# ESP32-P4 register map
Vendor: ESPRESSIF SYSTEMS (SHANGHAI) CO., LTD.; Series: ESP32 P-Series; File version: 3
CPU: RV32IMAFC r0p0, little endian, no MPU, FPU, 0 interrupt priority bits
Address unit: 32 bits
Registers are 32-bit, read-write, reset 0x0 unless marked. A register's access mark holds for its fields unless they carry their own. Offsets are from the block's base; [hi:lo] are bit positions; {n}, {i} and the like mark numbered series; 'fields as' and 'values as' point back to an identical list.

## GPIO — General Purpose Input/Output
Base 0x500E0000
0x00 BT_SELECT — GPIO bit select register
  [31:0] BT_SEL
0x04 OUT — GPIO output register for GPIO0-31
  [31:0] DATA_ORIG
0x08 OUT_W1TS wo — GPIO output set register for GPIO0-31
0x0C OUT_W1TC wo — GPIO output clear register for GPIO0-31
0x10 OUT1 — GPIO output register for GPIO32-56
  [24:0] DATA_ORIG
0x14 OUT1_W1TS wo — GPIO output set register for GPIO32-56
  [24:0] OUT1_W1TS
0x18 OUT1_W1TC wo — GPIO output clear register for GPIO32-56
  [24:0] OUT1_W1TC
0x20 ENABLE — GPIO output enable register for GPIO0-31
  [31:0] DATA
0x24 ENABLE_W1TS wo — GPIO output enable set register for GPIO0-31
0x28 ENABLE_W1TC wo — GPIO output enable clear register for GPIO0-31
0x2C ENABLE1 — GPIO output enable register for GPIO32-56
  [24:0] DATA
0x30 ENABLE1_W1TS wo — GPIO output enable set register for GPIO32-56
  [24:0] ENABLE1_W1TS
0x34 ENABLE1_W1TC wo — GPIO output enable clear register for GPIO32-56
  [24:0] ENABLE1_W1TC
0x38 STRAP ro — pad strapping register
  [15:0] STRAPPING
0x3C IN ro — GPIO input register for GPIO0-31
  [31:0] DATA_NEXT
0x40 IN1 ro — GPIO input register for GPIO32-56
  [24:0] DATA_NEXT
0x44 STATUS — GPIO interrupt status register for GPIO0-31
  [31:0] INTERRUPT
0x48 STATUS_W1TS wo — GPIO interrupt status set register for GPIO0-31
0x4C STATUS_W1TC wo — GPIO interrupt status clear register for GPIO0-31
0x50 STATUS1 — GPIO interrupt status register for GPIO32-56
  [24:0] INTERRUPT
0x54 STATUS1_W1TS wo — GPIO interrupt status set register for GPIO32-56
  [24:0] STATUS1_W1TS
0x58 STATUS1_W1TC wo — GPIO interrupt status clear register for GPIO32-56
  [24:0] STATUS1_W1TC
0x5C INTR_0 ro — GPIO interrupt 0 status register for GPIO0-31
  [31:0] INT_0
0x60 INTR1_0 ro — GPIO interrupt 0 status register for GPIO32-56
  [24:0] INT1_0
0x64 INTR_1 ro — GPIO interrupt 1 status register for GPIO0-31
  [31:0] INT_1
0x68 INTR1_1 ro — GPIO interrupt 1 status register for GPIO32-56
  [24:0] INT1_1
0x6C STATUS_NEXT ro — GPIO interrupt source register for GPIO0-31
  [31:0] STATUS_INTERRUPT_NEXT
0x70 STATUS_NEXT1 ro — GPIO interrupt source register for GPIO32-56
  [24:0] STATUS_INTERRUPT_NEXT1
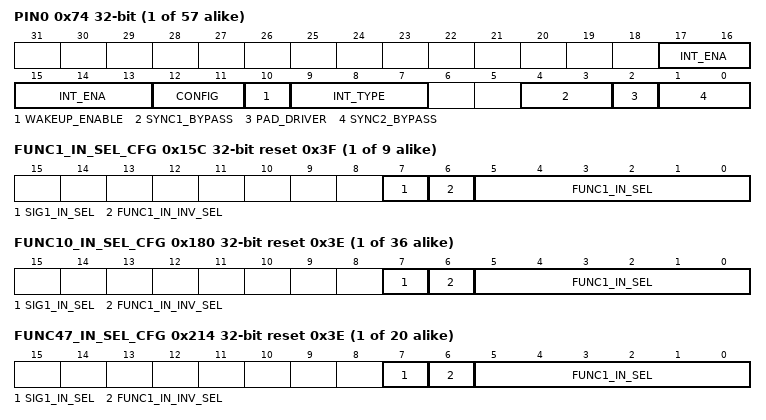
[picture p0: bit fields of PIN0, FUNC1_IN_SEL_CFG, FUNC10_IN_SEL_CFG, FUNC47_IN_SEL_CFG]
{0x74+4i} PIN{i} (i=0..56) — GPIO pin configuration register
  [17:13] INT_ENA — set bit 13 to enable CPU interrupt. set bit 14 to enable CPU(not shielded) interrupt.
  [12:11] CONFIG — reserved
  [10] WAKEUP_ENABLE — set this bit to enable GPIO wakeup.(can only wakeup CPU from Light-sleep Mode)
  [9:7] INT_TYPE — set this value to choose interrupt mode. 0:disable GPIO interrupt. 1:trigger at posedge. 2:trigger at negedge. 3:trigger at any edge. 4:valid at low level. 5:valid at high level
  [4:3] SYNC1_BYPASS — set GPIO input_sync1 signal mode. 0:disable. 1:trigger at negedge. 2or3:trigger at posedge.
  [2] PAD_DRIVER — set this bit to select pad driver. 1:open-drain. 0:normal.
  [1:0] SYNC2_BYPASS — set GPIO input_sync2 signal mode. 0:disable. 1:trigger at negedge. 2or3:trigger at posedge.
{0x158+4i} FUNC{i}_IN_SEL_CFG reset 0x3F (i=1..9) — GPIO input function configuration register
  [7] SIG{i}_IN_SEL — set this bit to bypass GPIO. 1:do not bypass GPIO. 0:bypass GPIO.
  [6] FUNC{i}_IN_INV_SEL — set this bit to invert input signal. 1:invert. 0:not invert.
  [5:0] FUNC{i}_IN_SEL — set this value: s=0-56: connect GPIO[s] to this port. s=0x3F: set this port always high level. s=0x3E: set this port always low level.
{0x158+4i} FUNC{i}_IN_SEL_CFG reset 0x3E (i=10..45) — GPIO input function configuration register
  fields as FUNC1_IN_SEL_CFG
{0x158+4i} FUNC{i}_IN_SEL_CFG reset 0x3E (i=47..66) — GPIO input function configuration register
  fields as FUNC1_IN_SEL_CFG
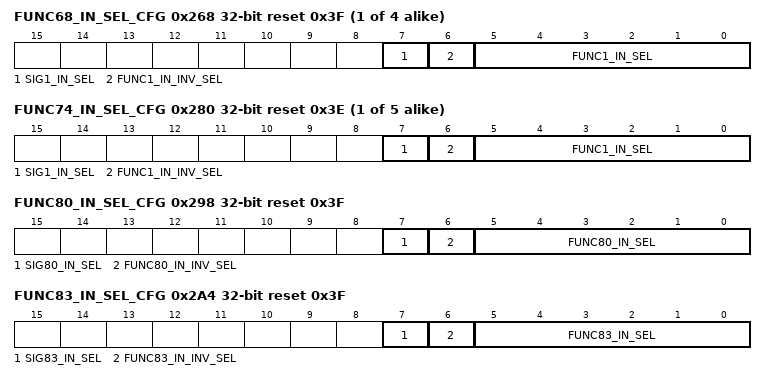
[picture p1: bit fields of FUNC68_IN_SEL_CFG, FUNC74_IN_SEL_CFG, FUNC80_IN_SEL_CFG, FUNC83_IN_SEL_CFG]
{0x158+4i} FUNC{i}_IN_SEL_CFG reset 0x3F (i=68..71) — GPIO input function configuration register
  fields as FUNC1_IN_SEL_CFG
{0x158+4i} FUNC{i}_IN_SEL_CFG reset 0x3E (i=74..78) — GPIO input function configuration register
  fields as FUNC1_IN_SEL_CFG
0x298 FUNC80_IN_SEL_CFG reset 0x3F — GPIO input function configuration register
  [7] SIG80_IN_SEL — set this bit to bypass GPIO. 1:do not bypass GPIO. 0:bypass GPIO.
  [6] FUNC80_IN_INV_SEL — set this bit to invert input signal. 1:invert. 0:not invert.
  [5:0] FUNC80_IN_SEL — set this value: s=0-56: connect GPIO[s] to this port. s=0x3F: set this port always high level. s=0x3E: set this port always low level.
0x2A4 FUNC83_IN_SEL_CFG reset 0x3F — GPIO input function configuration register
  [7] SIG83_IN_SEL — set this bit to bypass GPIO. 1:do not bypass GPIO. 0:bypass GPIO.
  [6] FUNC83_IN_INV_SEL — set this bit to invert input signal. 1:invert. 0:not invert.
  [5:0] FUNC83_IN_SEL — set this value: s=0-56: connect GPIO[s] to this port. s=0x3F: set this port always high level. s=0x3E: set this port always low level.
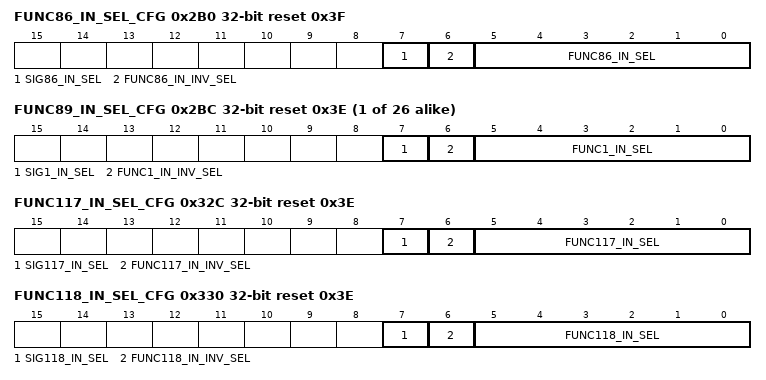
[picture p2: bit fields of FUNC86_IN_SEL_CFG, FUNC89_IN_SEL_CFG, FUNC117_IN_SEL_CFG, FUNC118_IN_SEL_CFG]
0x2B0 FUNC86_IN_SEL_CFG reset 0x3F — GPIO input function configuration register
  [7] SIG86_IN_SEL — set this bit to bypass GPIO. 1:do not bypass GPIO. 0:bypass GPIO.
  [6] FUNC86_IN_INV_SEL — set this bit to invert input signal. 1:invert. 0:not invert.
  [5:0] FUNC86_IN_SEL — set this value: s=0-56: connect GPIO[s] to this port. s=0x3F: set this port always high level. s=0x3E: set this port always low level.
{0x158+4i} FUNC{i}_IN_SEL_CFG reset 0x3E (i=89..114) — GPIO input function configuration register
  fields as FUNC1_IN_SEL_CFG
0x32C FUNC117_IN_SEL_CFG reset 0x3E — GPIO input function configuration register
  [7] SIG117_IN_SEL — set this bit to bypass GPIO. 1:do not bypass GPIO. 0:bypass GPIO.
  [6] FUNC117_IN_INV_SEL — set this bit to invert input signal. 1:invert. 0:not invert.
  [5:0] FUNC117_IN_SEL — set this value: s=0-56: connect GPIO[s] to this port. s=0x3F: set this port always high level. s=0x3E: set this port always low level.
0x330 FUNC118_IN_SEL_CFG reset 0x3E — GPIO input function configuration register
  [7] SIG118_IN_SEL — set this bit to bypass GPIO. 1:do not bypass GPIO. 0:bypass GPIO.
  [6] FUNC118_IN_INV_SEL — set this bit to invert input signal. 1:invert. 0:not invert.
  [5:0] FUNC118_IN_SEL — set this value: s=0-56: connect GPIO[s] to this port. s=0x3F: set this port always high level. s=0x3E: set this port always low level.
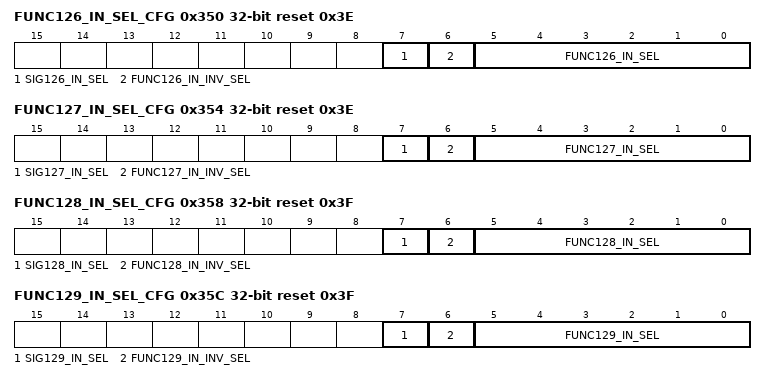
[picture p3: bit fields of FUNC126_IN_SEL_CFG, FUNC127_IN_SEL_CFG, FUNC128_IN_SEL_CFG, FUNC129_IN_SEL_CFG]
0x350 FUNC126_IN_SEL_CFG reset 0x3E — GPIO input function configuration register
  [7] SIG126_IN_SEL — set this bit to bypass GPIO. 1:do not bypass GPIO. 0:bypass GPIO.
  [6] FUNC126_IN_INV_SEL — set this bit to invert input signal. 1:invert. 0:not invert.
  [5:0] FUNC126_IN_SEL — set this value: s=0-56: connect GPIO[s] to this port. s=0x3F: set this port always high level. s=0x3E: set this port always low level.
0x354 FUNC127_IN_SEL_CFG reset 0x3E — GPIO input function configuration register
  [7] SIG127_IN_SEL — set this bit to bypass GPIO. 1:do not bypass GPIO. 0:bypass GPIO.
  [6] FUNC127_IN_INV_SEL — set this bit to invert input signal. 1:invert. 0:not invert.
  [5:0] FUNC127_IN_SEL — set this value: s=0-56: connect GPIO[s] to this port. s=0x3F: set this port always high level. s=0x3E: set this port always low level.
0x358 FUNC128_IN_SEL_CFG reset 0x3F — GPIO input function configuration register
  [7] SIG128_IN_SEL — set this bit to bypass GPIO. 1:do not bypass GPIO. 0:bypass GPIO.
  [6] FUNC128_IN_INV_SEL — set this bit to invert input signal. 1:invert. 0:not invert.
  [5:0] FUNC128_IN_SEL — set this value: s=0-56: connect GPIO[s] to this port. s=0x3F: set this port always high level. s=0x3E: set this port always low level.
0x35C FUNC129_IN_SEL_CFG reset 0x3F — GPIO input function configuration register
  [7] SIG129_IN_SEL — set this bit to bypass GPIO. 1:do not bypass GPIO. 0:bypass GPIO.
  [6] FUNC129_IN_INV_SEL — set this bit to invert input signal. 1:invert. 0:not invert.
  [5:0] FUNC129_IN_SEL — set this value: s=0-56: connect GPIO[s] to this port. s=0x3F: set this port always high level. s=0x3E: set this port always low level.
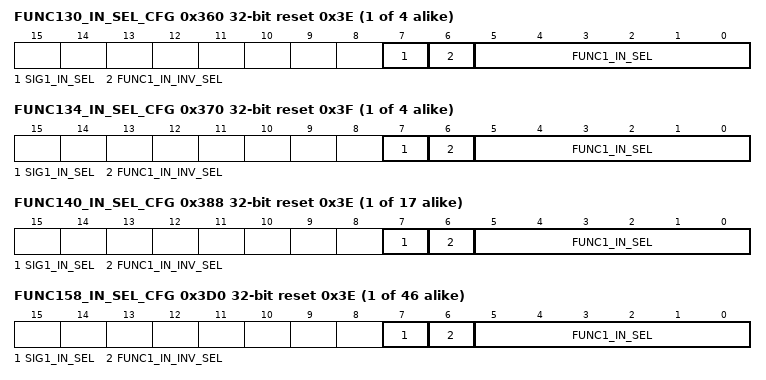
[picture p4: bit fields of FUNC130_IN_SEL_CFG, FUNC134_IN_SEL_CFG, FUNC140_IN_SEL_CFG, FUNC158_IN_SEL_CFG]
{0x158+4i} FUNC{i}_IN_SEL_CFG reset 0x3E (i=130..133) — GPIO input function configuration register
  fields as FUNC1_IN_SEL_CFG
{0x158+4i} FUNC{i}_IN_SEL_CFG reset 0x3F (i=134..137) — GPIO input function configuration register
  fields as FUNC1_IN_SEL_CFG
{0x158+4i} FUNC{i}_IN_SEL_CFG reset 0x3E (i=140..156) — GPIO input function configuration register
  fields as FUNC1_IN_SEL_CFG
{0x158+4i} FUNC{i}_IN_SEL_CFG reset 0x3E (i=158..203) — GPIO input function configuration register
  fields as FUNC1_IN_SEL_CFG
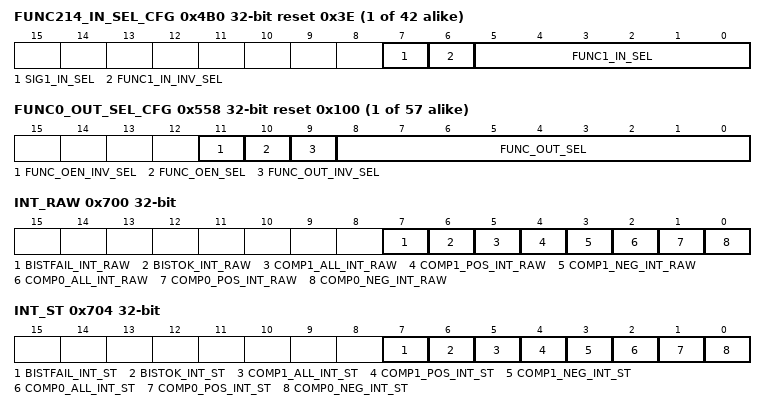
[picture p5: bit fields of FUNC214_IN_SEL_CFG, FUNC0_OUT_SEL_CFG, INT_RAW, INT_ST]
{0x158+4i} FUNC{i}_IN_SEL_CFG reset 0x3E (i=214..255) — GPIO input function configuration register
  fields as FUNC1_IN_SEL_CFG
{0x558+4i} FUNC{i}_OUT_SEL_CFG (i=0..56) reset 0x100 — GPIO output function select register
  [11] FUNC_OEN_INV_SEL — set this bit to invert output enable signal.1:invert.0:not invert.
  [10] FUNC_OEN_SEL — set this bit to select output enable signal.1:use GPIO_ENABLE_REG[n] as output enable signal.0:use peripheral output enable signal.
  [9] FUNC_OUT_INV_SEL — set this bit to invert output signal.1:invert.0:not invert.
  [8:0] FUNC_OUT_SEL — The value of the bits: 0<=s<=256. Set the value to select output signal. s=0-255: output of GPIO[n] equals input of peripheral[s]. s=256: output of GPIO[n] equals GPIO_OUT_REG[n].
0x63C INTR_2 ro — GPIO interrupt 2 status register for GPIO0-31
  [31:0] INT_2
0x640 INTR1_2 ro — GPIO interrupt 2 status register for GPIO32-56
  [24:0] INT1_2
0x644 INTR_3 ro — GPIO interrupt 3 status register for GPIO0-31
  [31:0] INT_3
0x648 INTR1_3 ro — GPIO interrupt 3 status register for GPIO32-56
  [24:0] INT1_3
0x64C CLOCK_GATE reset 0x1 — GPIO clock gate register
  [0] CLK_EN — set this bit to enable GPIO clock gate
0x700 INT_RAW — analog comparator interrupt raw
  [7] BISTFAIL_INT_RAW — pad bistfail interrupt raw
  [6] BISTOK_INT_RAW — pad bistok interrupt raw
  [5] COMP1_ALL_INT_RAW — analog comparator neg or pos edge interrupt raw
  [4] COMP1_POS_INT_RAW — analog comparator neg edge interrupt raw
  [3] COMP1_NEG_INT_RAW — analog comparator pos edge interrupt raw
  [2] COMP0_ALL_INT_RAW — analog comparator neg or pos edge interrupt raw
  [1] COMP0_POS_INT_RAW — analog comparator neg edge interrupt raw
  [0] COMP0_NEG_INT_RAW — analog comparator pos edge interrupt raw
0x704 INT_ST ro — analog comparator interrupt status
  [7] BISTFAIL_INT_ST — pad bistfail interrupt status
  [6] BISTOK_INT_ST — pad bistok interrupt status
  [5] COMP1_ALL_INT_ST — analog comparator neg or pos edge interrupt status
  [4] COMP1_POS_INT_ST — analog comparator neg edge interrupt status
  [3] COMP1_NEG_INT_ST — analog comparator pos edge interrupt status
  [2] COMP0_ALL_INT_ST — analog comparator neg or pos edge interrupt status
  [1] COMP0_POS_INT_ST — analog comparator neg edge interrupt status
  [0] COMP0_NEG_INT_ST — analog comparator pos edge interrupt status
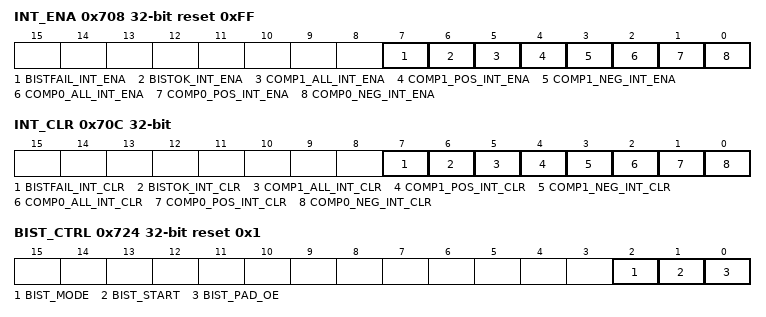
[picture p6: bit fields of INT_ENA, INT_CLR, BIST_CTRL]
0x708 INT_ENA reset 0xFF — analog comparator interrupt enable
  [7] BISTFAIL_INT_ENA — pad bistfail interrupt enable
  [6] BISTOK_INT_ENA — pad bistok interrupt enable
  [5] COMP1_ALL_INT_ENA — analog comparator neg or pos edge interrupt enable
  [4] COMP1_POS_INT_ENA — analog comparator neg edge interrupt enable
  [3] COMP1_NEG_INT_ENA — analog comparator pos edge interrupt enable
  [2] COMP0_ALL_INT_ENA — analog comparator neg or pos edge interrupt enable
  [1] COMP0_POS_INT_ENA — analog comparator neg edge interrupt enable
  [0] COMP0_NEG_INT_ENA — analog comparator pos edge interrupt enable
0x70C INT_CLR wo — analog comparator interrupt clear
  [7] BISTFAIL_INT_CLR — pad bistfail interrupt enable
  [6] BISTOK_INT_CLR — pad bistok interrupt enable
  [5] COMP1_ALL_INT_CLR — analog comparator neg or pos edge interrupt clear
  [4] COMP1_POS_INT_CLR — analog comparator neg edge interrupt clear
  [3] COMP1_NEG_INT_CLR — analog comparator pos edge interrupt clear
  [2] COMP0_ALL_INT_CLR — analog comparator neg or pos edge interrupt clear
  [1] COMP0_POS_INT_CLR — analog comparator neg edge interrupt clear
  [0] COMP0_NEG_INT_CLR — analog comparator pos edge interrupt clear
0x710 ZERO_DET0_FILTER_CNT reset 0xFFFFFFFF — GPIO analog comparator zero detect filter count
0x714 ZERO_DET1_FILTER_CNT reset 0xFFFFFFFF — GPIO analog comparator zero detect filter count
0x718 SEND_SEQ reset 0x12345678 — High speed sdio pad bist send sequence
0x71C RECIVE_SEQ ro — High speed sdio pad bist recive sequence
0x720 BISTIN_SEL reset 0xF — High speed sdio pad bist in pad sel
  [3:0] BISTIN_SEL — High speed sdio pad bist in pad sel 0:pad39, 1: pad40...
0x724 BIST_CTRL access per field reset 0x1 — High speed sdio pad bist control
  [2] BIST_MODE rw — Set 1 to enable sdio pad ddr200 bist mode
  [1] BIST_START wo — High speed sdio pad bist start
  [0] BIST_PAD_OE rw — High speed sdio pad bist out pad oe
0x7FC DATE reset 0x241226 — GPIO version register
  [27:0] DATE — version register
